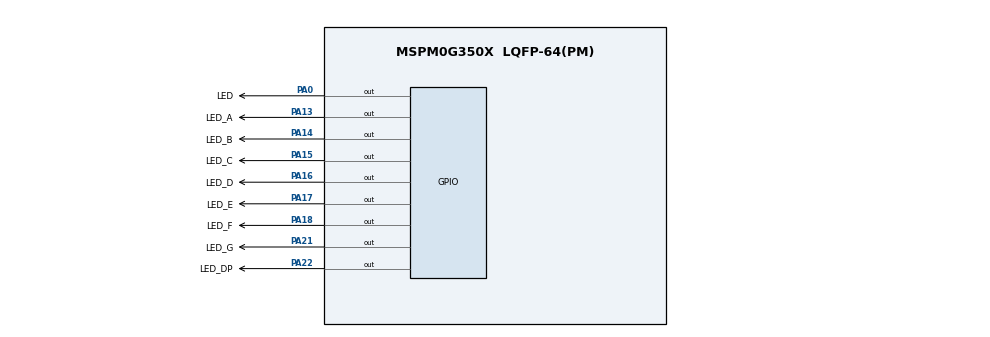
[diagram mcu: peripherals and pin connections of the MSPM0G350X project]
/**
 * @cliArgs --device "MSPM0G350X" --package "LQFP-64(PM)" --part "Default" --product "mspm0_sdk@1.20.01.06"
 * @versions {"tool":"1.18.0+3266"}
 */

/**
 * Import the modules used in this configuration.
 */
const Board  = scripting.addModule("/ti/driverlib/Board");
const GPIO   = scripting.addModule("/ti/driverlib/GPIO", {}, false);
const GPIO1  = GPIO.addInstance();
const SYSCTL = scripting.addModule("/ti/driverlib/SYSCTL");

/**
 * Write custom configuration values to the imported modules.
 */

GPIO1.port                          = "PORTA";
GPIO1.$name                         = "GPIO_LEDS";
GPIO1.associatedPins.create(9);
GPIO1.associatedPins[0].$name       = "LED";
GPIO1.associatedPins[0].pin.$assign = "PA0";
GPIO1.associatedPins[1].$name       = "LED_A";
GPIO1.associatedPins[1].pin.$assign = "PA13";
GPIO1.associatedPins[2].$name       = "LED_B";
GPIO1.associatedPins[2].pin.$assign = "PA14";
GPIO1.associatedPins[3].$name       = "LED_C";
GPIO1.associatedPins[3].pin.$assign = "PA15";
GPIO1.associatedPins[4].$name       = "LED_D";
GPIO1.associatedPins[4].pin.$assign = "PA16";
GPIO1.associatedPins[5].$name       = "LED_E";
GPIO1.associatedPins[5].pin.$assign = "PA17";
GPIO1.associatedPins[6].$name       = "LED_F";
GPIO1.associatedPins[6].pin.$assign = "PA18";
GPIO1.associatedPins[7].$name       = "LED_G";
GPIO1.associatedPins[7].pin.$assign = "PA21";
GPIO1.associatedPins[8].$name       = "LED_DP";
GPIO1.associatedPins[8].pin.$assign = "PA22";

SYSCTL.forceDefaultClkConfig = true;
SYSCTL.clockTreeEn           = true;

/**
 * Pinmux solution for unlocked pins/peripherals. This ensures that minor changes to the automatic solver in a future
 * version of the tool will not impact the pinmux you originally saw.  These lines can be completely deleted in order to
 * re-solve from scratch.
 */
Board.peripheral.$suggestSolution          = "DEBUGSS";
Board.peripheral.swclkPin.$suggestSolution = "PA20";
Board.peripheral.swdioPin.$suggestSolution = "PA19";
